# M3351 register map
File version: 1.0
Registers are 32-bit, read-write, reset 0x0 unless marked. A register's access mark holds for its fields unless they carry their own. Offsets are from the block's base; [hi:lo] are bit positions.

## QSPI0 — QSPI Register Map
Base 0x40060000
Same registers: QSPI0_NS 0x50060000
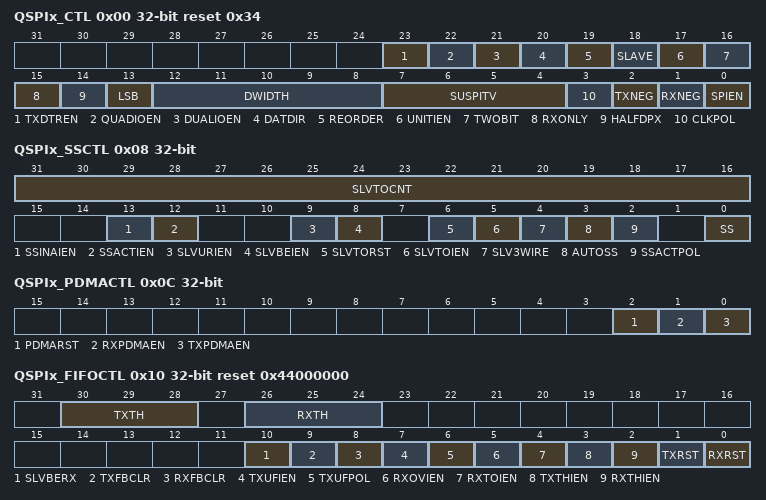
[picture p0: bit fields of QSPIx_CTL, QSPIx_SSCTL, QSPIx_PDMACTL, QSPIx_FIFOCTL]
0x00 QSPIx_CTL reset 0x34 — QSPI Control Register
  [23] TXDTREN — Transmit Double Transfer Rate Mode Enable Bit. Note: QSPI Master mode supports TXDTR mode, and QSPI Slave mode does not support this mode.
    0=TX DTR (Transmit Double Transfer Rate) mode Disabled; 1=TX DTR (Transmit Double Transfer Rate) mode Enabled
  [22] QUADIOEN — Quad I/O Mode Enable Bit
    0=Quad I/O mode Disabled; 1=Quad I/O mode Enabled
  [21] DUALIOEN — Dual I/O Mode Enable Bit
    0=Dual I/O mode Disabled; 1=Dual I/O mode Enabled
  [20] DATDIR — Data Port Direction Control. This bit is used to select the data input/output direction in half-duplex transfer and Dual/Quad transfer
    0=QSPI data is input direction; 1=QSPI data is output direction
  [19] REORDER — Byte Reorder Function Enable Bit. Note: Byte Reorder function is only available if DWIDTH is defined as 16, 24, and 32 bits.
    0=Byte Reorder function Disabled; 1=Byte Reorder function Enabled. A byte suspend interval will be inserted among each byte. The period of the byte suspend interval depends on the setting of SUSPITV
  [18] SLAVE — Slave Mode Control
    0=Master mode; 1=Slave mode
  [17] UNITIEN — Unit Transfer Interrupt Enable Bit
    0=QSPI unit transfer interrupt Disabled; 1=QSPI unit transfer interrupt Enabled
  [16] TWOBIT — 2-bit Transfer Mode Enable Bit. Note: When 2-bit Transfer mode is enabled, the first serial transmitted bit data is from the first FIFO buffer data, and the 2nd serial transmitted bit data is from the second FIFO buffer data. As the same as transmitted function, the first received bit data is stored into the first FIFO buffer and the 2nd received bit data is stored into the second FIFO buffer at the same time.
    0=2-bit Transfer mode Disabled; 1=2-bit Transfer mode Enabled
  [15] RXONLY — Receive-only Mode Enable Bit. This bit field is only available in Master mode. In receive-only mode, QSPI Master will generate QSPI bus clock continuously for receiving data bit from SPI slave device and assert the BUSY status.
    0=Receive-only mode Disabled; 1=Receive-only mode Enabled
  [14] HALFDPX — QSPI Half-duplex Transfer Enable Bit. This bit is used to select full-duplex or half-duplex for QSPI transfer. The bit field DATDIR (QSPIx_CTL[20]) can be used to set the data direction in half-duplex transfer.
    0=QSPI operates in full-duplex transfer; 1=QSPI operates in half-duplex transfer
  [13] LSB — Send LSB First
    0=The MSB, which bit of transmit/receive register depends on the setting of DWIDTH, is transmitted/received first; 1=The LSB, bit 0 of the QSPIx TX register, is sent first to the QSPI data output pin, and the first bit received from the QSPI data input pin will be put in the LSB position of the RX register (bit 0 of QSPIx_RX)
  [12:8] DWIDTH — Data Width. This field specifies how many bits can be transmitted/received in one transaction. The minimum bit length is 8 bits and can up to 32 bits.
  [7:4] SUSPITV — Suspend Interval. The four bits provide configurable suspend interval between two successive transmit/receive transaction in a transfer. The definition of the suspend interval is the interval between the last clock edge of the preceding transaction word and the first clock edge of the following transaction word. The default value is 0x3. The period of the suspend interval is obtained according to the following equation. (SUSPITV[3:0] + 0.5) * period of QSPI_CLK clock cycle. Example: Note: Master only and in TX DTR mode, SUSPITV equals to 0x0.
  [3] CLKPOL — Clock Polarity
    0=QSPI bus clock is idle low; 1=QSPI bus clock is idle high
  [2] TXNEG — Transmit on Negative Edge. Note: In TX DTR mode, TXNEG equals to CLKPOL (QSPIx_CTL[3]).
    0=Transmitted data output signal is changed on the rising edge of QSPI bus clock; 1=Transmitted data output signal is changed on the falling edge of QSPI bus clock
  [1] RXNEG — Receive on Negative Edge
    0=Received data input signal is latched on the rising edge of QSPI bus clock; 1=Received data input signal is latched on the falling edge of QSPI bus clock
  [0] SPIEN — QSPI Transfer Control Enable Bit. In Master mode, the transfer will start when there is data in the FIFO buffer after this bit is set to 1. In Slave mode, this device is ready to receive data when this bit is set to 1. Note: Before changing the configurations of QSPIx_CTL, QSPIx_CLKDIV, QSPIx_SSCTL and QSPIx_FIFOCTL registers, user shall clear the SPIEN (QSPIx_CTL[0]) and confirm the SPIENSTS (QSPIx_STATUS[15]) is 0.
    0=Transfer control Disabled; 1=Transfer control Enabled
0x04 QSPIx_CLKDIV — QSPI Clock Divider Register
  [8:0] DIVIDER — Clock Divider. The value in this field is the frequency divider for generating the peripheral clock, fspi_eclk, and the QSPI bus clock of QSPI Master. The frequency is obtained according to the following equation. where is the peripheral clock source, which is defined in the clock control register, CLK_CLKSEL2. Note: The time interval must be larger than or equal to 8 peripheral clock cycles between releasing QSPI IP software reset and setting this clock divider register.
0x08 QSPIx_SSCTL — QSPI Slave Select Control Register
  [31:16] SLVTOCNT — Slave Mode Time-out Period. In Slave mode, these bits indicate the time-out period when there is bus clock input during slave select active. The clock source of the time-out counter is Slave peripheral clock. If the value is 0, it indicates the Slave mode time-out function is disabled.
  [13] SSINAIEN — Slave Select Inactive Interrupt Enable Bit
    0=Slave select inactive interrupt Disabled; 1=Slave select inactive interrupt Enabled
  [12] SSACTIEN — Slave Select Active Interrupt Enable Bit
    0=Slave select active interrupt Disabled; 1=Slave select active interrupt Enabled
  [9] SLVURIEN — Slave Mode TX Under Run Interrupt Enable Bit
    0=Slave mode TX under run interrupt Disabled; 1=Slave mode TX under run interrupt Enabled
  [8] SLVBEIEN — Slave Mode Bit Count Error Interrupt Enable Bit
    0=Slave mode bit count error interrupt Disabled; 1=Slave mode bit count error interrupt Enabled
  [6] SLVTORST — Slave Mode Time-out Reset Control
    0=When Slave mode time-out event occurs, the TX and RX control circuit will not be reset; 1=When Slave mode time-out event occurs, the TX and RX control circuit will be reset by hardware
  [5] SLVTOIEN — Slave Mode Time-out Interrupt Enable Bit
    0=Slave mode time-out interrupt Disabled; 1=Slave mode time-out interrupt Enabled
  [4] SLV3WIRE — Slave 3-wire Mode Enable Bit. In Slave 3-wire mode, the QSPI controller can work with 3-wire interface including QSPIx_CLK, QSPIx_MISO and QSPIx_MOSI pins. Note: This bit is Slave only.
    0=4-wire bi-direction interface; 1=3-wire bi-direction interface
  [3] AUTOSS — Automatic Slave Selection Function Enable Bit. Note: This bit is Master only.
    0=Automatic slave selection function Disabled. Slave selection signal will be asserted/de-asserted according to SS (QSPIx_SSCTL[0]); 1=Automatic slave selection function Enabled
  [2] SSACTPOL — Slave Selection Active Polarity. This bit defines the active polarity of slave selection signal (QSPIx_SS).
    0=The slave selection signal QSPIx_SS is active low; 1=The slave selection signal QSPIx_SS is active high
  [0] SS — Slave Selection Control. If AUTOSS bit is cleared to 0, Note: This bit is Master only. Note
    0=Set the QSPIx_SS line to inactive state. Keep the QSPIx_SS line at inactive state; 1=Set the QSPIx_SS line to active state. QSPIx_SS line will be automatically driven to active state for the duration of data transfer, and will be driven to inactive state for the rest of the time. The active state of QSPIx_SS is specified in SSACTPOL (QSPIx_SSCTL[2])
0x0C QSPIx_PDMACTL — QSPI PDMA Control Register
  [2] PDMARST — PDMA Reset
    0=No effect; 1=Reset the PDMA control logic of the QSPI controller. This bit will be automatically cleared to 0
  [1] RXPDMAEN — Receive PDMA Enable Bit
    0=Receive PDMA function Disabled; 1=Receive PDMA function Enabled
  [0] TXPDMAEN — Transmit PDMA Enable Bit. Note 1: In QSPI Master mode with full duplex transfer, if both TX and RX PDMA functions are enabled, RX PDMA function cannot be enabled prior to TX PDMA function. User can enable TX PDMA function firstly or enable both functions simultaneously. Note 2: In QSPI Master mode with full duplex transfer, if both TX and RX PDMA functions are enabled, TX PDMA function cannot be disabled prior to RX PDMA function. User can disable RX PDMA function firstly or disable both functions simultaneously.
    0=Transmit PDMA function Disabled; 1=Transmit PDMA function Enabled
0x10 QSPIx_FIFOCTL reset 0x44000000 — QSPI FIFO Control Register
  [30:28] TXTH — Transmit FIFO Threshold. If the valid data count of the transmit FIFO buffer is less than or equal to the TXTH setting, the TXTHIF bit will be set to 1, else the TXTHIF bit will be cleared to 0.
  [26:24] RXTH — Receive FIFO Threshold. If the valid data count of the receive FIFO buffer is larger than the RXTH setting, the RXTHIF bit will be set to 1, else the RXTHIF bit will be cleared to 0.
  [10] SLVBERX — RX FIFO Write Data Enable Bit When Slave Mode Bit Count Error. Note: This bit is Slave only.
    0=Uncompleted RX data will be dropped from RX FIFO when bit count error event happen in QSPI Slave mode; 1=Uncompleted RX data will be written into RX FIFO when bit count error event happen in QSPI Slave mode. User can read SLVBENUM (QSPIx_STATUS2[29:24]) to know that the effective bit number of uncompleted RX data when SPI slave bit count error happened
  [9] TXFBCLR — Transmit FIFO Buffer Clear. Note: The TX shift register will not be cleared.
    0=No effect; 1=Clear transmit FIFO pointer. The TXFULL bit will be cleared to 0 and the TXEMPTY bit will be set to 1. This bit will be cleared to 0 by hardware about 1 system clock after it is set to 1
  [8] RXFBCLR — Receive FIFO Buffer Clear. Note: The RX shift register will not be cleared.
    0=No effect; 1=Clear receive FIFO pointer. The RXFULL bit will be cleared to 0 and the RXEMPTY bit will be set to 1. This bit will be cleared to 0 by hardware about 1 system clock after it is set to 1
  [7] TXUFIEN — TX Underflow Interrupt Enable Bit. When TX underflow event occurs in Slave mode, TXUFIF (QSPIx_STATUS[19]) will be set to 1. This bit is used to enable the TX underflow interrupt.
    0=Slave TX underflow interrupt Disabled; 1=Slave TX underflow interrupt Enabled
  [6] TXUFPOL — TX Underflow Data Polarity. Note 1: The TX underflow event occurs if there is no any data in TX FIFO when the slave selection signal is active. Note 2: When TX underflow event occurs, QSPIx_MISO pin state will be determined by this setting even though TX FIFO is not empty afterward. Data stored in TX FIFO will be sent through QSPIx_MISO pin in the next transfer frame.
    0=The QSPI data out is kept 0 if there is TX underflow event in Slave mode; 1=The QSPI data out is kept 1 if there is TX underflow event in Slave mode
  [5] RXOVIEN — Receive FIFO Overrun Interrupt Enable Bit
    0=Receive FIFO overrun interrupt Disabled; 1=Receive FIFO overrun interrupt Enabled
  [4] RXTOIEN — Receive Time-out Interrupt Enable Bit
    0=Receive time-out interrupt Disabled; 1=Receive time-out interrupt Enabled
  [3] TXTHIEN — Transmit FIFO Threshold Interrupt Enable Bit
    0=TX FIFO threshold interrupt Disabled; 1=TX FIFO threshold interrupt Enabled
  [2] RXTHIEN — Receive FIFO Threshold Interrupt Enable Bit
    0=RX FIFO threshold interrupt Disabled; 1=RX FIFO threshold interrupt Enabled
  [1] TXRST — Transmit Reset. Note: If TX underflow event occurs in QSPI Slave mode, this bit can be used to make QSPI return to idle state.
    0=No effect; 1=Reset transmit FIFO pointer and transmit circuit. The TXFULL bit will be cleared to 0 and the TXEMPTY bit will be set to 1. This bit will be cleared to 0 by hardware about 3 system clock cycles + 2 peripheral clock cycles after it is set to 1. User can read TXRXRST (QSPIx_STATUS[23]) to check if reset is accomplished or not
  [0] RXRST — Receive Reset
    0=No effect; 1=Reset receive FIFO pointer and receive circuit. The RXFULL bit will be cleared to 0 and the RXEMPTY bit will be set to 1. This bit will be cleared to 0 by hardware about 3 system clock cycles + 2 peripheral clock cycles after it is set to 1. User can read TXRXRST (QSPIx_STATUS[23]) to check if reset is accomplished or not
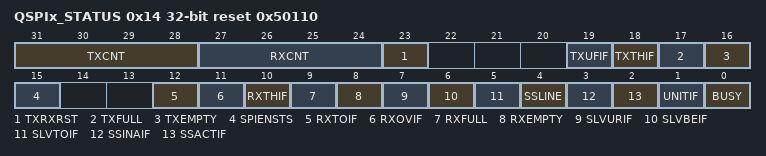
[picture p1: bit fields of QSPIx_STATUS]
0x14 QSPIx_STATUS reset 0x50110 — QSPI Status Register
  [31:28] TXCNT — Transmit FIFO Data Count (Read Only). This bit field indicates the valid data count of transmit FIFO buffer.
  [27:24] RXCNT — Receive FIFO Data Count (Read Only). This bit field indicates the valid data count of receive FIFO buffer.
  [23] TXRXRST — TX or RX Reset Status (Read Only). Note: Both the reset operations of TXRST and RXRST need 3 system clock cycles + 2 peripheral clock cycles. User can check the status of this bit to monitor the reset function is doing or done.
    0=The reset function of TXRST or RXRST is done; 1=Doing the reset function of TXRST or RXRST
  [19] TXUFIF — TX Underflow Interrupt Flag. When the TX underflow event occurs, this bit will be set to 1, the state of data output pin depends on the setting of TXUFPOL. Note 1: This bit will be cleared by writing 1 to it. Note 2: If reset slave's transmission circuit when slave selection signal is active, this flag will be set to 1 after 2 peripheral clock cycles + 3 system clock cycles since the reset operation is done.
    0=No effect; 1=No data in Transmit FIFO and TX shift register when the slave selection signal is active
  [18] TXTHIF — Transmit FIFO Threshold Interrupt Flag (Read Only)
    0=The valid data count within the transmit FIFO buffer is larger than the setting value of TXTH; 1=The valid data count within the transmit FIFO buffer is less than or equal to the setting value of TXTH
  [17] TXFULL — Transmit FIFO Buffer Full Indicator (Read Only)
    0=Transmit FIFO buffer is not full; 1=Transmit FIFO buffer is full
  [16] TXEMPTY — Transmit FIFO Buffer Empty Indicator (Read Only)
    0=Transmit FIFO buffer is not empty; 1=Transmit FIFO buffer is empty
  [15] SPIENSTS — QSPI Enable Status (Read Only). Note: The QSPI peripheral clock is asynchronous with the system clock. In order to make sure the QSPI control logic is disabled, this bit indicates the real status of QSPI controller.
    0=QSPI controller Disabled; 1=QSPI controller Enabled
  [12] RXTOIF — Receive Time-out Interrupt Flag. Note: This bit will be cleared by writing 1 to it.
    0=No receive FIFO time-out event; 1=Receive FIFO buffer is not empty and no read operation on receive FIFO buffer over 64 QSPI peripheral clock periods in Master mode or over 576 QSPI peripheral clock periods in Slave mode. When the received FIFO buffer is read by software, the time-out status will be cleared automatically
  [11] RXOVIF — Receive FIFO Overrun Interrupt Flag. When the receive FIFO buffer is full, the follow-up data will be dropped and this bit will be set to 1. Note 1: This bit will be cleared by writing 1 to it. Note 2: If the RXONLY is enabled, the SPI bus length for one transaction shall greater than 5 ECLK + 2 PCLK, otherwise this flag will be set. (e.g. 8-bit length quad mode, there is 2 bit bus cycle only and it is less than the limitation above).
    0=No FIFO is overrun; 1=Receive FIFO is overrun
  [10] RXTHIF — Receive FIFO Threshold Interrupt Flag (Read Only)
    0=The valid data count within the receive FIFO buffer is smaller than or equal to the setting value of RXTH; 1=The valid data count within the receive FIFO buffer is larger than the setting value of RXTH
  [9] RXFULL — Receive FIFO Buffer Full Indicator (Read Only)
    0=Receive FIFO buffer is not full; 1=Receive FIFO buffer is full
  [8] RXEMPTY — Receive FIFO Buffer Empty Indicator (Read Only)
    0=Receive FIFO buffer is not empty; 1=Receive FIFO buffer is empty
  [7] SLVURIF — Slave Mode TX Under Run Interrupt Flag. In Slave mode, if TX underflow event occurs and the slave select line goes to inactive state, this interrupt flag will be set to 1. Note: This bit will be cleared by writing 1 to it.
    0=No Slave TX under run event; 1=Slave TX under run event occurred
  [6] SLVBEIF — Slave Mode Bit Count Error Interrupt Flag. In Slave mode, when the slave select line goes to inactive state, if bit counter is mismatch with DWIDTH, this interrupt flag will be set to 1. Note: If the slave select active but there is no any bus clock input, the SLVBEIF also active when the slave select goes to inactive state. This bit will be cleared by writing 1 to it.
    0=No Slave mode bit count error event; 1=Slave mode bit count error event occurred
  [5] SLVTOIF — Slave Time-out Interrupt Flag. When the slave select is active and the value of SLVTOCNT is not 0, if the bus clock is detected, the slave time-out counter in QSPI controller logic will be started. When the value of time-out counter is greater than or equal to the value of SLVTOCNT (QSPIx_SSCTL[31:16]) before one transaction is done, the slave time-out interrupt event will be asserted. Note: This bit will be cleared by writing 1 to it.
    0=Slave time-out is not active; 1=Slave time-out is active
  [4] SSLINE — Slave Select Line Bus Status (Read Only). Note: This bit is only available in Slave mode. If SSACTPOL (QSPIx_SSCTL[2]) is set 0, and the SSLINE is 1, the QSPI slave select is in inactive status.
    0=The slave select line status is 0; 1=The slave select line status is 1
  [3] SSINAIF — Slave Select Inactive Interrupt Flag. Note: Only available in Slave mode. This bit will be cleared by writing 1 to it.
    0=Slave select inactive interrupt was cleared or not occurred; 1=Slave select inactive interrupt event occurred
  [2] SSACTIF — Slave Select Active Interrupt Flag. Note: Only available in Slave mode. This bit will be cleared by writing 1 to it.
    0=Slave select active interrupt was cleared or not occurred; 1=Slave select active interrupt event occurred
  [1] UNITIF — Unit Transfer Interrupt Flag. Note: This bit will be cleared by writing 1 to it.
    0=No transaction has been finished since this bit was cleared to 0; 1=QSPI controller has finished one unit transfer
  [0] BUSY — Busy Status (Read Only). Note: By applications, this QSPI busy flag should be used with other status registers in QSPIx_STATUS such as TXCNT, RXCNT, TXTHIF, TXFULL, TXEMPTY, RXTHIF, RXFULL, RXEMPTY, and UNITIF. Therefore the QSPI transfer done events of TX/RX operations can be obtained at correct timing point.
    0=QSPI controller is in idle state; 1=QSPI controller is in busy state
0x18 QSPIx_STATUS2 ro — QSPI Status2 Register
  [29:24] SLVBENUM — Effective Bit Number of Uncompleted RX Data. This status register indicates that effective bit number of uncompleted RX data when SLVBERX (QSPIx_FIFOCTL[10]) is enabled and RX bit count error event happen in QSPI Slave mode. This status register will be fixed to 0x0 when SLVBERX (QSPIx_FIFOCTL[10]) is disabled. Note: This register will be cleared to 0x0 when user write 0x1 to SLVBEIF (QSPIx_STATUS[6]). Note: This bit is Slave only.
0x20 QSPIx_TX wo — QSPI Data Transmit Register
  [31:0] TX — Data Transmit Register. The data transmit registers pass through the transmitted data into the 8-level transmit FIFO buffers. The number of valid bits depends on the setting of DWIDTH (QSPIx_CTL[12:8]) in QSPI mode. In QSPI mode, if DWIDTH is set to 0x08, the bits TX[7:0] will be transmitted. If DWIDTH is set to 0x00, the QSPI controller will perform a 32-bit transfer. Note: In Master mode, QSPI controller will start to transfer the QSPI bus clock after 1 APB clock and 6 peripheral clock cycles after user writes to this register.
0x30 QSPIx_RX ro — QSPI Data Receive Register
  [31:0] RX — Data Receive Register (Read Only). There are 8-level FIFO buffers in this controller The data receive register holds the data received from QSPI data input pin If the RXEMPTY (QSPIx_STATUS[8) is not set to 1, the receive FIFO buffers can be accessed through software by reading this register.
